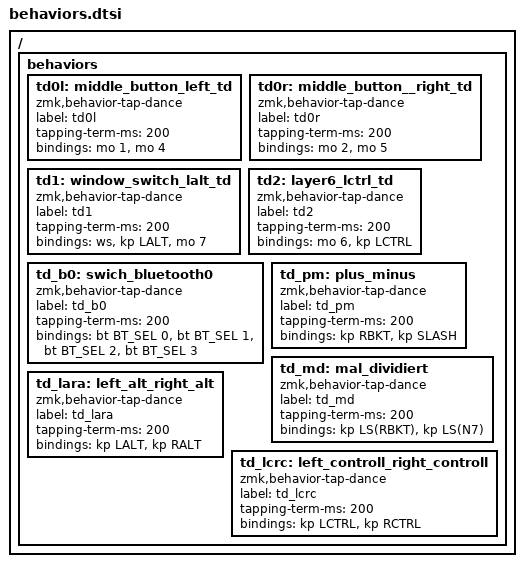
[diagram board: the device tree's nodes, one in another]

/ {
    behaviors {
        td0l: middle_button_left_td {
            compatible = "zmk,behavior-tap-dance";
            label = "td0l";
            #binding-cells = <0>;
            tapping-term-ms = <200>;
            bindings = <&mo 1>, <&mo 4>;
        };

        td0r: middle_button__right_td {
            compatible = "zmk,behavior-tap-dance";
            label = "td0r";
            #binding-cells = <0>;
            tapping-term-ms = <200>;
            bindings = <&mo 2>, <&mo 5>;
        };

        td1: window_switch_lalt_td {
            compatible = "zmk,behavior-tap-dance";
            label = "td1";
            #binding-cells = <0>;
            tapping-term-ms = <200>;
            bindings = <&ws>, <&kp LALT>, <&mo 7>;
        };

        td2: layer6_lctrl_td {
            compatible = "zmk,behavior-tap-dance";
            label = "td2";
            #binding-cells = <0>;
            tapping-term-ms = <200>;
            bindings = <&mo 6>, <&kp LCTRL>;
        };

        td_b0: swich_bluetooth0 {
            compatible = "zmk,behavior-tap-dance";
            label = "td_b0";
            #binding-cells = <0>;
            tapping-term-ms = <200>;
            bindings =
                <&bt BT_SEL 0>,
                <&bt BT_SEL 1>,
                <&bt BT_SEL 2>,
                <&bt BT_SEL 3>;
        };

        td_pm: plus_minus {
            compatible = "zmk,behavior-tap-dance";
            label = "td_pm";
            #binding-cells = <0>;
            tapping-term-ms = <200>;
            bindings = <&kp RBKT>, <&kp SLASH>;
        };

        td_md: mal_dividiert {
            compatible = "zmk,behavior-tap-dance";
            label = "td_md";
            #binding-cells = <0>;
            tapping-term-ms = <200>;
            bindings = <&kp LS(RBKT)>, <&kp LS(N7)>;
        };

        td_lara: left_alt_right_alt {
            compatible = "zmk,behavior-tap-dance";
            label = "td_lara";
            #binding-cells = <0>;
            tapping-term-ms = <200>;
            bindings = <&kp LALT>, <&kp RALT>;
        };

        td_lcrc: left_controll_right_controll {
            compatible = "zmk,behavior-tap-dance";
            label = "td_lcrc";
            #binding-cells = <0>;
            tapping-term-ms = <200>;
            bindings = <&kp LCTRL>, <&kp RCTRL>;
        };
    };
};
